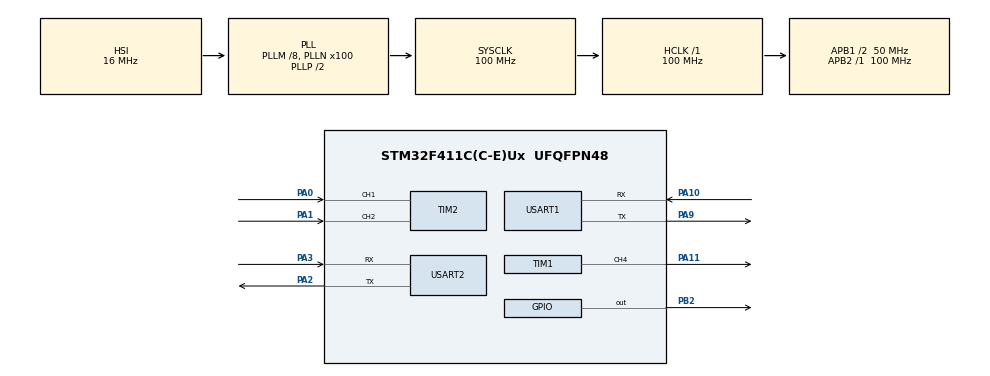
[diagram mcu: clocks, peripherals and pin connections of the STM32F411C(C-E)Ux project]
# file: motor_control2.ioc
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Mcu.Family=STM32F4
Mcu.Name=STM32F411C(C-E)Ux
Mcu.Package=UFQFPN48
NVIC.PriorityGroup=NVIC_PRIORITYGROUP_4
NVIC.TIM4_IRQn=true\:0\:0\:false\:false\:true\:true\:true\:true
PA0-WKUP.Signal=S_TIM2_CH1_ETR
PA1.Signal=S_TIM2_CH2
PA10.Mode=Asynchronous
PA10.Signal=USART1_RX
PA11.Signal=S_TIM1_CH4
PA13.Mode=Trace_Asynchronous_SW
PA13.Signal=SYS_JTMS-SWDIO
PA14.Mode=Trace_Asynchronous_SW
PA14.Signal=SYS_JTCK-SWCLK
PA2.Mode=Asynchronous
PA2.Signal=USART2_TX
PA3.Mode=Asynchronous
PA3.Signal=USART2_RX
PA9.Mode=Asynchronous
PA9.Signal=USART1_TX
PB2.Signal=GPIO_Output
PB3.Mode=Trace_Asynchronous_SW
PB3.Signal=SYS_JTDO-SWO
PC14-OSC32_IN.Mode=LSE-External-Oscillator
PC14-OSC32_IN.Signal=RCC_OSC32_IN
PC15-OSC32_OUT.Mode=LSE-External-Oscillator
PC15-OSC32_OUT.Signal=RCC_OSC32_OUT
PH0\ -\ OSC_IN.Mode=HSE-External-Oscillator
PH0\ -\ OSC_IN.Signal=RCC_OSC_IN
PH1\ -\ OSC_OUT.Mode=HSE-External-Oscillator
PH1\ -\ OSC_OUT.Signal=RCC_OSC_OUT
ProjectManager.HeapSize=0x200
ProjectManager.StackSize=0x400
ProjectManager.TargetToolchain=STM32CubeIDE
RCC.48MHZClocksFreq_Value=50000000
RCC.AHBFreq_Value=100000000
RCC.APB1CLKDivider=RCC_HCLK_DIV2
RCC.APB1Freq_Value=50000000
RCC.APB1TimFreq_Value=100000000
RCC.APB2Freq_Value=100000000
RCC.APB2TimFreq_Value=100000000
RCC.CortexFreq_Value=100000000
RCC.HCLKFreq_Value=100000000
RCC.HSE_VALUE=25000000
RCC.HSI_VALUE=16000000
RCC.PLLM=8
RCC.PLLN=100
RCC.SYSCLKFreq_VALUE=100000000
RCC.SYSCLKSource=RCC_SYSCLKSOURCE_PLLCLK
RCC.VCOOutputFreq_Value=200000000
SH.S_TIM1_CH4.0=TIM1_CH4,PWM Generation4 CH4
SH.S_TIM2_CH1_ETR.0=TIM2_CH1,Encoder_Interface
SH.S_TIM2_CH2.0=TIM2_CH2,Encoder_Interface
TIM1.Channel-PWM\ Generation4\ CH4=TIM_CHANNEL_4
TIM4.Period=65535
TIM4.Prescaler=100-1
USART1.VirtualMode=VM_ASYNC
USART2.VirtualMode=VM_ASYNC
VP_TIM1_VS_ClockSourceINT.Mode=Internal
VP_TIM4_VS_ClockSourceINT.Mode=Internal
board=custom

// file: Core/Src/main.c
/* USER CODE BEGIN Header */
/**
  ******************************************************************************
  * @file           : main.c
  * @brief          : Main program body
  ******************************************************************************
  * @attention
  *
  * Copyright (c) 2026 STMicroelectronics.
  * All rights reserved.
  *
  * This software is licensed under terms that can be found in the LICENSE file
  * in the root directory of this software component.
  * If no LICENSE file comes with this software, it is provided AS-IS.
  *
  ******************************************************************************
  */
/* USER CODE END Header */
#include "main.h"

/* USER CODE BEGIN Includes */
#include <stdio.h>
#include "motor_control.h"
/* USER CODE END Includes */

TIM_HandleTypeDef htim1;
TIM_HandleTypeDef htim2;
TIM_HandleTypeDef htim4;

UART_HandleTypeDef huart1;
UART_HandleTypeDef huart2;

void SystemClock_Config(void);
static void MX_GPIO_Init(void);
static void MX_TIM1_Init(void);
static void MX_TIM2_Init(void);
static void MX_TIM4_Init(void);
static void MX_USART1_UART_Init(void);
static void MX_USART2_UART_Init(void);

/* USER CODE BEGIN 0 */

//int _write(int file, char *ptr, int len) {
//    extern UART_HandleTypeDef huart2; // Replace huart2 with your active UART handle (e.g. huart1)
//    HAL_UART_Transmit(&huart2, (uint8_t *)ptr, len, 100);
//    return len;
//}

int _write(int file, char *ptr, int len)
{
	int i=0;
	for(i=0;i<len;i++)
	{
		ITM_SendChar((*ptr++));
	}
	return len;
}
/* USER CODE END 0 */

int main(void)
{

  /* MCU Configuration--------------------------------------------------------*/

  /* Reset of all peripherals, Initializes the Flash interface and the Systick. */
  HAL_Init();

  /* Configure the system clock */
  SystemClock_Config();

  /* Initialize all configured peripherals */
  MX_GPIO_Init();
  MX_TIM1_Init();
  MX_TIM2_Init();
  MX_TIM4_Init();
  MX_USART1_UART_Init();
  MX_USART2_UART_Init();
  /* USER CODE BEGIN 2 */
  MotorControl_Init();           // Starts timers and motor outputs
  HAL_TIM_Base_Start_IT(&htim4); // Starts your 10ms hardware control interrupt
  /* USER CODE END 2 */

  /* Infinite loop */
  while (1)
  {

  }
}

void SystemClock_Config(void)
{
  RCC_OscInitTypeDef RCC_OscInitStruct = {0};
  RCC_ClkInitTypeDef RCC_ClkInitStruct = {0};

  /** Configure the main internal regulator output voltage
  */
  __HAL_RCC_PWR_CLK_ENABLE();
  __HAL_PWR_VOLTAGESCALING_CONFIG(PWR_REGULATOR_VOLTAGE_SCALE1);

  /** Initializes the RCC Oscillators according to the specified parameters
  * in the RCC_OscInitTypeDef structure.
  */
  RCC_OscInitStruct.OscillatorType = RCC_OSCILLATORTYPE_HSI;
  RCC_OscInitStruct.HSIState = RCC_HSI_ON;
  RCC_OscInitStruct.HSICalibrationValue = RCC_HSICALIBRATION_DEFAULT;
  RCC_OscInitStruct.PLL.PLLState = RCC_PLL_ON;
  RCC_OscInitStruct.PLL.PLLSource = RCC_PLLSOURCE_HSI;
  RCC_OscInitStruct.PLL.PLLM = 8;
  RCC_OscInitStruct.PLL.PLLN = 100;
  RCC_OscInitStruct.PLL.PLLP = RCC_PLLP_DIV2;
  RCC_OscInitStruct.PLL.PLLQ = 4;
  if (HAL_RCC_OscConfig(&RCC_OscInitStruct) != HAL_OK)
  {
    Error_Handler();
  }

  /** Initializes the CPU, AHB and APB buses clocks
  */
  RCC_ClkInitStruct.ClockType = RCC_CLOCKTYPE_HCLK|RCC_CLOCKTYPE_SYSCLK
                              |RCC_CLOCKTYPE_PCLK1|RCC_CLOCKTYPE_PCLK2;
  RCC_ClkInitStruct.SYSCLKSource = RCC_SYSCLKSOURCE_PLLCLK;
  RCC_ClkInitStruct.AHBCLKDivider = RCC_SYSCLK_DIV1;
  RCC_ClkInitStruct.APB1CLKDivider = RCC_HCLK_DIV2;
  RCC_ClkInitStruct.APB2CLKDivider = RCC_HCLK_DIV1;

  if (HAL_RCC_ClockConfig(&RCC_ClkInitStruct, FLASH_LATENCY_3) != HAL_OK)
  {
    Error_Handler();
  }
}

static void MX_TIM1_Init(void)
{

  TIM_ClockConfigTypeDef sClockSourceConfig = {0};
  TIM_MasterConfigTypeDef sMasterConfig = {0};
  TIM_OC_InitTypeDef sConfigOC = {0};
  TIM_BreakDeadTimeConfigTypeDef sBreakDeadTimeConfig = {0};

  htim1.Instance = TIM1;
  htim1.Init.Prescaler = 0;
  htim1.Init.CounterMode = TIM_COUNTERMODE_UP;
  htim1.Init.Period = 65535;
  htim1.Init.ClockDivision = TIM_CLOCKDIVISION_DIV1;
  htim1.Init.RepetitionCounter = 0;
  htim1.Init.AutoReloadPreload = TIM_AUTORELOAD_PRELOAD_DISABLE;
  if (HAL_TIM_Base_Init(&htim1) != HAL_OK)
  {
    Error_Handler();
  }
  sClockSourceConfig.ClockSource = TIM_CLOCKSOURCE_INTERNAL;
  if (HAL_TIM_ConfigClockSource(&htim1, &sClockSourceConfig) != HAL_OK)
  {
    Error_Handler();
  }
  if (HAL_TIM_PWM_Init(&htim1) != HAL_OK)
  {
    Error_Handler();
  }
  sMasterConfig.MasterOutputTrigger = TIM_TRGO_RESET;
  sMasterConfig.MasterSlaveMode = TIM_MASTERSLAVEMODE_DISABLE;
  if (HAL_TIMEx_MasterConfigSynchronization(&htim1, &sMasterConfig) != HAL_OK)
  {
    Error_Handler();
  }
  sConfigOC.OCMode = TIM_OCMODE_PWM1;
  sConfigOC.Pulse = 0;
  sConfigOC.OCPolarity = TIM_OCPOLARITY_HIGH;
  sConfigOC.OCFastMode = TIM_OCFAST_DISABLE;
  sConfigOC.OCIdleState = TIM_OCIDLESTATE_RESET;
  sConfigOC.OCNIdleState = TIM_OCNIDLESTATE_RESET;
  if (HAL_TIM_PWM_ConfigChannel(&htim1, &sConfigOC, TIM_CHANNEL_4) != HAL_OK)
  {
    Error_Handler();
  }
  sBreakDeadTimeConfig.OffStateRunMode = TIM_OSSR_DISABLE;
  sBreakDeadTimeConfig.OffStateIDLEMode = TIM_OSSI_DISABLE;
  sBreakDeadTimeConfig.LockLevel = TIM_LOCKLEVEL_OFF;
  sBreakDeadTimeConfig.DeadTime = 0;
  sBreakDeadTimeConfig.BreakState = TIM_BREAK_DISABLE;
  sBreakDeadTimeConfig.BreakPolarity = TIM_BREAKPOLARITY_HIGH;
  sBreakDeadTimeConfig.AutomaticOutput = TIM_AUTOMATICOUTPUT_DISABLE;
  if (HAL_TIMEx_ConfigBreakDeadTime(&htim1, &sBreakDeadTimeConfig) != HAL_OK)
  {
    Error_Handler();
  }
  HAL_TIM_MspPostInit(&htim1);

}

static void MX_TIM2_Init(void)
{

  TIM_Encoder_InitTypeDef sConfig = {0};
  TIM_MasterConfigTypeDef sMasterConfig = {0};

  htim2.Instance = TIM2;
  htim2.Init.Prescaler = 0;
  htim2.Init.CounterMode = TIM_COUNTERMODE_UP;
  htim2.Init.Period = 4294967295;
  htim2.Init.ClockDivision = TIM_CLOCKDIVISION_DIV1;
  htim2.Init.AutoReloadPreload = TIM_AUTORELOAD_PRELOAD_DISABLE;
  sConfig.EncoderMode = TIM_ENCODERMODE_TI1;
  sConfig.IC1Polarity = TIM_ICPOLARITY_RISING;
  sConfig.IC1Selection = TIM_ICSELECTION_DIRECTTI;
  sConfig.IC1Prescaler = TIM_ICPSC_DIV1;
  sConfig.IC1Filter = 0;
  sConfig.IC2Polarity = TIM_ICPOLARITY_RISING;
  sConfig.IC2Selection = TIM_ICSELECTION_DIRECTTI;
  sConfig.IC2Prescaler = TIM_ICPSC_DIV1;
  sConfig.IC2Filter = 0;
  if (HAL_TIM_Encoder_Init(&htim2, &sConfig) != HAL_OK)
  {
    Error_Handler();
  }
  sMasterConfig.MasterOutputTrigger = TIM_TRGO_RESET;
  sMasterConfig.MasterSlaveMode = TIM_MASTERSLAVEMODE_DISABLE;
  if (HAL_TIMEx_MasterConfigSynchronization(&htim2, &sMasterConfig) != HAL_OK)
  {
    Error_Handler();
  }

}

static void MX_TIM4_Init(void)
{

  TIM_ClockConfigTypeDef sClockSourceConfig = {0};
  TIM_MasterConfigTypeDef sMasterConfig = {0};

  htim4.Instance = TIM4;
  htim4.Init.Prescaler = 100-1;
  htim4.Init.CounterMode = TIM_COUNTERMODE_UP;
  htim4.Init.Period = 65535;
  htim4.Init.ClockDivision = TIM_CLOCKDIVISION_DIV1;
  htim4.Init.AutoReloadPreload = TIM_AUTORELOAD_PRELOAD_DISABLE;
  if (HAL_TIM_Base_Init(&htim4) != HAL_OK)
  {
    Error_Handler();
  }
  sClockSourceConfig.ClockSource = TIM_CLOCKSOURCE_INTERNAL;
  if (HAL_TIM_ConfigClockSource(&htim4, &sClockSourceConfig) != HAL_OK)
  {
    Error_Handler();
  }
  sMasterConfig.MasterOutputTrigger = TIM_TRGO_RESET;
  sMasterConfig.MasterSlaveMode = TIM_MASTERSLAVEMODE_DISABLE;
  if (HAL_TIMEx_MasterConfigSynchronization(&htim4, &sMasterConfig) != HAL_OK)
  {
    Error_Handler();
  }

}

static void MX_USART1_UART_Init(void)
{

  huart1.Instance = USART1;
  huart1.Init.BaudRate = 115200;
  huart1.Init.WordLength = UART_WORDLENGTH_8B;
  huart1.Init.StopBits = UART_STOPBITS_1;
  huart1.Init.Parity = UART_PARITY_NONE;
  huart1.Init.Mode = UART_MODE_TX_RX;
  huart1.Init.HwFlowCtl = UART_HWCONTROL_NONE;
  huart1.Init.OverSampling = UART_OVERSAMPLING_16;
  if (HAL_UART_Init(&huart1) != HAL_OK)
  {
    Error_Handler();
  }

}

static void MX_USART2_UART_Init(void)
{

  huart2.Instance = USART2;
  huart2.Init.BaudRate = 115200;
  huart2.Init.WordLength = UART_WORDLENGTH_8B;
  huart2.Init.StopBits = UART_STOPBITS_1;
  huart2.Init.Parity = UART_PARITY_NONE;
  huart2.Init.Mode = UART_MODE_TX_RX;
  huart2.Init.HwFlowCtl = UART_HWCONTROL_NONE;
  huart2.Init.OverSampling = UART_OVERSAMPLING_16;
  if (HAL_UART_Init(&huart2) != HAL_OK)
  {
    Error_Handler();
  }

}

static void MX_GPIO_Init(void)
{
  GPIO_InitTypeDef GPIO_InitStruct = {0};

  /* GPIO Ports Clock Enable */
  __HAL_RCC_GPIOC_CLK_ENABLE();
  __HAL_RCC_GPIOH_CLK_ENABLE();
  __HAL_RCC_GPIOA_CLK_ENABLE();
  __HAL_RCC_GPIOB_CLK_ENABLE();

  /*Configure GPIO pin Output Level */
  HAL_GPIO_WritePin(GPIOB, GPIO_PIN_2, GPIO_PIN_RESET);

  /*Configure GPIO pin : PB2 */
  GPIO_InitStruct.Pin = GPIO_PIN_2;
  GPIO_InitStruct.Mode = GPIO_MODE_OUTPUT_PP;
  GPIO_InitStruct.Pull = GPIO_NOPULL;
  GPIO_InitStruct.Speed = GPIO_SPEED_FREQ_LOW;
  HAL_GPIO_Init(GPIOB, &GPIO_InitStruct);

}

/* USER CODE BEGIN 4 */
void HAL_TIM_PeriodElapsedCallback(TIM_HandleTypeDef *htim) {
    if (htim->Instance == TIM4) {
        MotorControl_Update(0.01f); // Executes 100Hz PID calculation loop
    }
}
/* USER CODE END 4 */

void Error_Handler(void)
{
  __disable_irq();
  while (1)
  {
  }
}
